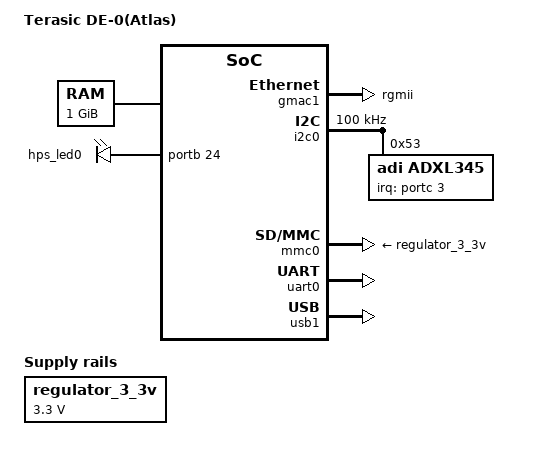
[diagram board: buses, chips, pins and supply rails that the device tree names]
#include "socfpga_cyclone5.dtsi"
/ {
	model = "Terasic DE-0(Atlas)";
	compatible = "terasic,de0-atlas", "altr,socfpga-cyclone5", "altr,socfpga";
	chosen {
		bootargs = "earlyprintk";
		stdout-path = "serial0:115200n8";
	};
	memory@0 {
		name = "memory";
		device_type = "memory";
		reg = <0x0 0x40000000>;  
	};
	aliases {
		ethernet0 = &gmac1;
	};
	regulator_3_3v: regulator {
		compatible = "regulator-fixed";
		regulator-name = "3.3V";
		regulator-min-microvolt = <3300000>;
		regulator-max-microvolt = <3300000>;
	};
	leds {
		compatible = "gpio-leds";
		led-hps0 {
			label = "hps_led0";
			gpios = <&portb 24 0>;
			linux,default-trigger = "heartbeat";
		};
	};
};
&gmac1 {
	status = "okay";
	phy-mode = "rgmii";
	txd0-skew-ps = <0>;  
	txd1-skew-ps = <0>;  
	txd2-skew-ps = <0>;  
	txd3-skew-ps = <0>;  
	rxd0-skew-ps = <420>;  
	rxd1-skew-ps = <420>;  
	rxd2-skew-ps = <420>;  
	rxd3-skew-ps = <420>;  
	txen-skew-ps = <0>;  
	txc-skew-ps = <1860>;  
	rxdv-skew-ps = <420>;  
	rxc-skew-ps = <1680>;  
	max-frame-size = <3800>;
};
&gpio0 {
	status = "okay";
};
&gpio1 {
	status = "okay";
};
&gpio2 {
	status = "okay";
};
&i2c0 {
	status = "okay";
	clock-frequency = <100000>;
	adxl345: adxl345@53 {
		compatible = "adi,adxl345";
		reg = <0x53>;
		interrupt-parent = <&portc>;
		interrupts = <3 2>;
	};
};
&mmc0 {
	vmmc-supply = <&regulator_3_3v>;
	vqmmc-supply = <&regulator_3_3v>;
	status = "okay";
};
&uart0 {
	status = "okay";
};
&usb1 {
	status = "okay";
};
